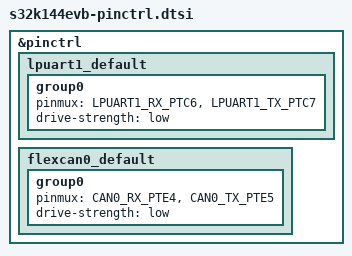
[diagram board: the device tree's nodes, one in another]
/*
 * Copyright (c) 2026 Maior Cristian-Alexandru
 * SPDX-License-Identifier: Apache-2.0
 */

#include <nxp/s32/S32K144_LQFP100-pinctrl.h>

&pinctrl {
	lpuart1_default: lpuart1_default {
		group0 {
			pinmux = <LPUART1_RX_PTC6>, <LPUART1_TX_PTC7>;
			drive-strength = "low";
		};
	};

	flexcan0_default: flexcan0_default {
		group0 {
			pinmux = <CAN0_RX_PTE4>, <CAN0_TX_PTE5>;
			drive-strength = "low";
		};
	};
};
